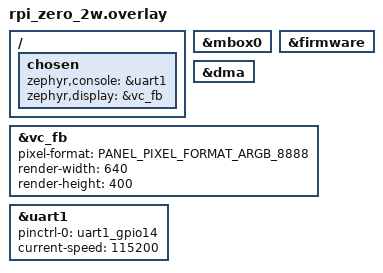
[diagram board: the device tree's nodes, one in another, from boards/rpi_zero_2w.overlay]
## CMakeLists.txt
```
# SPDX-License-Identifier: Apache-2.0
#
# PiZZa -- DOSBox-X on the shared SDL2 shim (apps/lib/sdl2shim).
#
# Links the DOSBox-X machine core (untouched checkout at
# ~/github/dosbox-x) against the shim, with the desktop chrome left out
# of the TU list and sdlmain.cpp replaced wholesale by
# src/sdlmain_embedded.cpp. TU selection and macro choices per
# notes/P2_SCOPE.md.
#
# DOSBox-X is GPL-2.0-or-later; this binary is GPL-2.0 by linking it.

cmake_minimum_required(VERSION 3.20.0)

find_package(Zephyr REQUIRED HINTS $ENV{ZEPHYR_BASE})
project(pizza-dosbox LANGUAGES C CXX ASM)

if(CONFIG_USB_DEVICE_STACK_NEXT)
  include(${ZEPHYR_BASE}/samples/subsys/usb/common/common.cmake)
endif()

# ── DOSBox-X tree (untouched) ───────────────────────────────────────
if(NOT DEFINED DBX)
  set(DBX "$ENV{HOME}/github/dosbox-x")
endif()
if(NOT EXISTS "${DBX}/src/dosbox.cpp")
  message(FATAL_ERROR
    "DOSBox-X sources not found at ${DBX}. Clone "
    "https://github.com/joncampbell123/dosbox-x or pass -DDBX=<path>.")
endif()
set(S ${DBX}/src)

# ── KEEP list (P2_SCOPE.md §5) ──────────────────────────────────────
# cpu: all cores except the x86-host-only dynamic_x86.
set(DBX_CPU
  ${S}/cpu/callback.cpp ${S}/cpu/cpu.cpp ${S}/cpu/flags.cpp
  ${S}/cpu/modrm.cpp ${S}/cpu/paging.cpp ${S}/cpu/mmx.cpp
  ${S}/cpu/core_full.cpp ${S}/cpu/core_simple.cpp
  ${S}/cpu/core_normal.cpp ${S}/cpu/core_normal_286.cpp
  ${S}/cpu/core_normal_8086.cpp ${S}/cpu/core_prefetch.cpp
  ${S}/cpu/core_prefetch_286.cpp ${S}/cpu/core_prefetch_8086.cpp
  ${S}/cpu/core_dynrec.cpp
)

set(DBX_FPU ${S}/fpu/fpu.cpp)

# dos: platform cdrom-ioctl variants and physfs dropped.
# cdrom_image.cpp rewritten in the build dir: the CHD prefetch thread
# (std::thread, no gthreads on Zephyr) is compiled out, taking the
# synchronous decode path instead. Checkout stays pristine (Doom
# i_video precedent).
set(DBX_CDIMG_GEN ${CMAKE_BINARY_DIR}/gen/cdrom_image_nothread.cpp)
add_custom_command(
  OUTPUT ${DBX_CDIMG_GEN}
  COMMAND ${CMAKE_COMMAND} -E make_directory ${CMAKE_BINARY_DIR}/gen
  COMMAND ${CMAKE_COMMAND} -E copy ${S}/dos/cdrom_image.cpp ${DBX_CDIMG_GEN}
  COMMAND sed -i.bak
          -e "s@#if !defined(HX_DOS) && !(defined(__MINGW32__) && !defined(__MINGW64_VERSION_MAJOR))@#if 0 /* no threads on Zephyr */@"
          -e "s@#if defined(HX_DOS) || defined(__MINGW32__) && !defined(__MINGW64_VERSION_MAJOR)@#if 1 /* sync CHD decode */@"
          ${DBX_CDIMG_GEN}
  DEPENDS ${S}/dos/cdrom_image.cpp
  COMMENT "Rewriting cdrom_image.cpp: CHD prefetch thread -> sync decode"
  VERBATIM
)

# dos_programs.cpp rewritten in the build dir: the physfs:// mount
# branches reference physfsDrive (vendored PhysFS not built); NULL the
# construction and casts, MOUNT reports failure on such paths.
set(DBX_DOSPROG_GEN ${CMAKE_BINARY_DIR}/gen/dos_programs_nophysfs.cpp)
add_custom_command(
  OUTPUT ${DBX_DOSPROG_GEN}
  COMMAND ${CMAKE_COMMAND} -E make_directory ${CMAKE_BINARY_DIR}/gen
  COMMAND ${CMAKE_COMMAND} -E copy ${S}/dos/dos_programs.cpp ${DBX_DOSPROG_GEN}
  COMMAND sed -i.bak
          -e "s@new physfscdromDrive@NULL; (void)@"
          -e "s@new physfsDrive@NULL; (void)@"
          -e "s@dynamic_cast<physfsDrive\\*>(Drives\\[drive-'A'\\])@NULL@"
          -e "s@dynamic_cast<physfscdromDrive\\*>(Drives\\[drive-'A'\\])@NULL@"
          ${DBX_DOSPROG_GEN}
  DEPENDS ${S}/dos/dos_programs.cpp
  COMMENT "Rewriting dos_programs.cpp: physfs mounts -> NULL"
  VERBATIM
)

# dos_files.cpp gets the same physfs treatment (savestate restore paths).
set(DBX_DOSFILES_GEN ${CMAKE_BINARY_DIR}/gen/dos_files_nophysfs.cpp)
add_custom_command(
  OUTPUT ${DBX_DOSFILES_GEN}
  COMMAND ${CMAKE_COMMAND} -E make_directory ${CMAKE_BINARY_DIR}/gen
  COMMAND ${CMAKE_COMMAND} -E copy ${S}/dos/dos_files.cpp ${DBX_DOSFILES_GEN}
  COMMAND sed -i.bak
          -e "s@if (strlen(overlaydir)) dynamic_cast<physfsDrive\\*>(Drives\\[lcv\\])->setOverlaydir(overlaydir);@;@"
          -e "s@dynamic_cast<physfsDrive\\*>(Drives\\[lcv\\])@NULL@g"
          -e "s@new physfscdromDrive@NULL; (void)@"
          -e "s@new physfsDrive@NULL; (void)@"
          ${DBX_DOSFILES_GEN}
  DEPENDS ${S}/dos/dos_files.cpp
  COMMENT "Rewriting dos_files.cpp: physfs savestate paths -> NULL"
  VERBATIM
)

set(DBX_DOS
  ${S}/dos/cdrom.cpp ${DBX_CDIMG_GEN}
  ${S}/dos/dos.cpp ${S}/dos/dos_classes.cpp ${S}/dos/dos_devices.cpp
  ${S}/dos/dos_execute.cpp ${DBX_DOSFILES_GEN} ${S}/dos/dos_ioctl.cpp
  ${S}/dos/dos_keyboard_layout.cpp ${S}/dos/dos_memory.cpp
  ${S}/dos/dos_misc.cpp ${S}/dos/dos_mscdex.cpp ${DBX_DOSPROG_GEN}
  ${S}/dos/dos_tables.cpp ${S}/dos/drive_cache.cpp ${S}/dos/drive_fat.cpp
  ${S}/dos/drive_iso.cpp ${S}/dos/drive_local.cpp
  ${S}/dos/drive_overlay.cpp ${S}/dos/drive_virtual.cpp
  ${S}/dos/drives.cpp ${S}/dos/eltorito.cpp
)

set(DBX_INTS
  ${S}/ints/bios.cpp ${S}/ints/bios_disk.cpp ${S}/ints/bios_keyboard.cpp
  ${S}/ints/bios_memdisk.cpp ${S}/ints/bios_vhd.cpp ${S}/ints/ems.cpp
  ${S}/ints/int10.cpp ${S}/ints/int10_char.cpp ${S}/ints/int10_memory.cpp
  ${S}/ints/int10_misc.cpp ${S}/ints/int10_modes.cpp
  ${S}/ints/int10_pal.cpp ${S}/ints/int10_put_pixel.cpp
  ${S}/ints/int10_vesa.cpp ${S}/ints/int10_video_state.cpp
  ${S}/ints/int10_vptable.cpp ${S}/ints/int_dosv.cpp ${S}/ints/mouse.cpp
  ${S}/ints/pc98_lio.cpp ${S}/ints/qcow2_disk.cpp ${S}/ints/xms.cpp
)

set(DBX_SHELL
  ${S}/shell/shell.cpp ${S}/shell/shell_batch.cpp
  ${S}/shell/shell_cmds.cpp ${S}/shell/shell_misc.cpp
)

# misc: ethernet dispatcher kept with the "nothing" backend only;
# pcap/slirp/ethnet and iconvpp dropped.
set(DBX_MISC
  ${S}/misc/clipboard.cpp ${S}/misc/cross.cpp ${S}/misc/ethernet.cpp
  ${S}/misc/ethernet_nothing.cpp ${S}/misc/messages.cpp
  ${S}/misc/mkdir_p.cpp ${S}/misc/programs.cpp
  ${S}/misc/regionalloctracking.cpp ${S}/misc/savestates.cpp
  ${S}/misc/setup.cpp ${S}/misc/shiftjis.cpp ${S}/misc/support.cpp
)

set(DBX_OUTPUT ${S}/output/output_surface.cpp ${S}/output/output_tools.cpp)

# gui: sdlmain.cpp REPLACED by sdlmain_embedded.cpp; sdl_gui/gui_tk and
# sdlmain_linux omitted.
# sdl_mapper.cpp rewritten in the build dir: the Typer autotype helper
# owns a std::thread (no gthreads on Zephyr); its start becomes a no-op.
set(DBX_MAPPER_GEN ${CMAKE_BINARY_DIR}/gen/sdl_mapper_nothread.cpp)
add_custom_command(
  OUTPUT ${DBX_MAPPER_GEN}
  COMMAND ${CMAKE_COMMAND} -E make_directory ${CMAKE_BINARY_DIR}/gen
  COMMAND ${CMAKE_COMMAND} -E copy ${S}/gui/sdl_mapper.cpp ${DBX_MAPPER_GEN}
  COMMAND sed -i.bak
          -e "s@m_instance = std::thread(&Typer::Callback, this);@/* autotype disabled (no threads) */@"
          -e "s@if (m_instance.joinable())@if (0)@"
          -e "s@m_instance.join();@{}@"
          -e "s@std::thread              m_instance;@/* no thread member */@"
          ${DBX_MAPPER_GEN}
  DEPENDS ${S}/gui/sdl_mapper.cpp
  COMMENT "Rewriting sdl_mapper.cpp: Typer std::thread -> no-op"
  VERBATIM
)

set(DBX_GUI
  ${S}/gui/bitop.cpp ${S}/gui/ptrop.cpp ${S}/gui/menu.cpp
  ${S}/gui/menu_callback.cpp ${S}/gui/midi.cpp ${S}/gui/render.cpp
  ${S}/gui/render_scalers.cpp ${DBX_MAPPER_GEN}
  ${S}/gui/zipcrc.c ${S}/gui/zipfile.cpp
)

# debug_gui carries LOG_MSG/logging even with C_DEBUG off.
set(DBX_DEBUG ${S}/debug/debug_gui.cpp)

# hardware: PC-98 display TUs kept dormant (symbols referenced from
# shared vga code); snd_pc98 + pc98_fm, voodoo/glide, network cards,
# serial-OPL boards, imfc (std::thread), innova (reSID) omitted.
set(DBX_HW
  ${S}/hardware/8255.cpp ${S}/hardware/adlib.cpp ${S}/hardware/cmos.cpp
  ${S}/hardware/cqm.c ${S}/hardware/dbopl.cpp ${S}/hardware/disney.cpp
  ${S}/hardware/dma.cpp ${S}/hardware/floppy.cpp
  ${S}/hardware/gameblaster.cpp ${S}/hardware/gus.cpp
  ${S}/hardware/hardware.cpp ${S}/hardware/ide.cpp
  ${S}/hardware/iohandler.cpp ${S}/hardware/joystick.cpp
  ${S}/hardware/keyboard.cpp ${S}/hardware/memory.cpp
  ${S}/hardware/mixer.cpp ${S}/hardware/mpu401.cpp
  ${S}/hardware/nukedopl.cpp ${S}/hardware/pc98.cpp
  ${S}/hardware/pc98_artic.cpp ${S}/hardware/pci_bus.cpp
  ${S}/hardware/pcspeaker.cpp ${S}/hardware/pic.cpp
  ${S}/hardware/ps1_sound.cpp ${S}/hardware/sblaster.cpp
  ${S}/hardware/tandy_sound.cpp ${S}/hardware/timer.cpp
  ${S}/hardware/vga.cpp ${S}/hardware/vga_ati.cpp
  ${S}/hardware/vga_attr.cpp ${S}/hardware/vga_crtc.cpp
  ${S}/hardware/vga_dac.cpp ${S}/hardware/vga_draw.cpp
  ${S}/hardware/vga_gfx.cpp ${S}/hardware/vga_memory.cpp
  ${S}/hardware/vga_misc.cpp ${S}/hardware/vga_other.cpp
  ${S}/hardware/vga_paradise.cpp ${S}/hardware/vga_pc98_cg.cpp
  ${S}/hardware/vga_pc98_crtc.cpp ${S}/hardware/vga_pc98_dac.cpp
  ${S}/hardware/vga_pc98_egc.cpp ${S}/hardware/vga_pc98_gdc.cpp
  ${S}/hardware/vga_pc98_gdc_draw.cpp ${S}/hardware/vga_s3.cpp
  ${S}/hardware/vga_seq.cpp ${S}/hardware/vga_tseng.cpp
  ${S}/hardware/vga_xga.cpp
  ${S}/hardware/esfmu/esfm.c ${S}/hardware/esfmu/esfm_registers.c
)

set(DBX_MAME
  ${S}/hardware/mame/fmopl.cpp ${S}/hardware/mame/saa1099.cpp
  ${S}/hardware/mame/sn76496.cpp ${S}/hardware/mame/ymdeltat.cpp
  ${S}/hardware/mame/ymf262.cpp
)

# serialport: no SDL_net consumers (softmodem/nullmodem/misc_util out);
# directserial needs real host termios, out (C_DIRECTSERIAL off).
# libserial compiles against the compat termios (its opens fail at
# runtime) and satisfies the serial-OPL boards below.
set(DBX_SERIAL
  ${S}/hardware/serialport/serialport.cpp
  ${S}/hardware/serialport/serialdummy.cpp
  ${S}/hardware/serialport/serialmouse.cpp
  ${S}/hardware/serialport/seriallog.cpp
  ${S}/hardware/serialport/serialfile.cpp
  ${S}/hardware/serialport/libserial.cpp
)

# adlib.cpp references the serial OPL boards + RetroWave unconditionally
# (runtime-gated on oplemu= choices we never use). RetroWave links real
# (compat termios suffices); the opl2/opl3duo boards own std::threads,
# so they are method stubs in lib_stubs.cpp instead.
set(DBX_OPLBOARDS
  ${S}/hardware/RetroWaveLib/RetroWave.c
  ${S}/hardware/RetroWaveLib/Protocol/Serial.c
  ${S}/hardware/RetroWaveLib/Board/OPL3.c
  ${S}/hardware/RetroWaveLib/Platform/POSIX_SerialPort.c
  ${S}/hardware/RetroWaveLib/RetroWave_DOSBoX.cpp
)

set(DBX_PARPORT
  ${S}/hardware/parport/parport.cpp
  ${S}/hardware/parport/filelpt.cpp
  ${S}/hardware/parport/printer_charmaps.cpp
)

# builtin DOS tools (baked binaries); glide2x + ne2000 bins omitted.
set(DBX_BUILTIN
  ${S}/builtin/25_com.cpp ${S}/builtin/28_com.cpp ${S}/builtin/4dos.cpp
  ${S}/builtin/50_com.cpp ${S}/builtin/append_exe.cpp
  ${S}/builtin/buffers_com.cpp ${S}/builtin/cdplay.cpp
  ${S}/builtin/chkdsk_exe.cpp ${S}/builtin/cwsdpmi_exe.cpp
  ${S}/builtin/cwsdpmi_exe_pc98.cpp ${S}/builtin/debug_exe.cpp
  ${S}/builtin/defrag_exe.cpp ${S}/builtin/device_com.cpp
  ${S}/builtin/diskcopy_exe.cpp ${S}/builtin/dos32a_exe.cpp
  ${S}/builtin/dos4gw_exe.cpp ${S}/builtin/dosidle_exe.cpp
  ${S}/builtin/dosmid.cpp ${S}/builtin/dsxmenu_exe_pc.cpp
  ${S}/builtin/dsxmenu_exe_pc98.cpp ${S}/builtin/edit_com.cpp
  ${S}/builtin/emsmagic.cpp ${S}/builtin/eval.cpp ${S}/builtin/fc_exe.cpp
  ${S}/builtin/fcbs_com.cpp ${S}/builtin/fdisk_exe.cpp
  ${S}/builtin/files_com.cpp ${S}/builtin/find_exe.cpp
  ${S}/builtin/format_exe.cpp ${S}/builtin/glide2x.cpp
  ${S}/builtin/ne2000bin.cpp ${S}/builtin/hexmem16_exe.cpp
  ${S}/builtin/hexmem32_exe.cpp ${S}/builtin/ipsmake.cpp
  ${S}/builtin/ipspatch.cpp ${S}/builtin/lastdriv_com.cpp
  ${S}/builtin/mem_com.cpp ${S}/builtin/move_exe.cpp
  ${S}/builtin/mpxplay.cpp ${S}/builtin/print_com.cpp
  ${S}/builtin/replace_exe.cpp ${S}/builtin/shutdown.cpp
  ${S}/builtin/sort_exe.cpp ${S}/builtin/sys_com.cpp
  ${S}/builtin/textutil.cpp ${S}/builtin/xcopy_exe.cpp
  ${S}/builtin/zip.cpp
)

# aviwriter: hardware.cpp references avi_writer_*/riff_wav_writer_*
# unconditionally (runtime-gated); self-contained, so link the real thing.
set(DBX_AVIWRITER
  ${S}/aviwriter/avi_writer.cpp ${S}/aviwriter/avi_rw_iobuf.cpp
  ${S}/aviwriter/guid.cpp ${S}/aviwriter/ksdataformat.cpp
  ${S}/aviwriter/riff.cpp ${S}/aviwriter/riff_wav_writer.cpp
)

# vendored zlib (vs/zlib): include/zip.h + savestates need it; the gz*
# file API is not used on the RAM-fd layer, left out.
set(DBX_ZLIB
  ${DBX}/vs/zlib/adler32.c ${DBX}/vs/zlib/compress.c
  ${DBX}/vs/zlib/crc32.c ${DBX}/vs/zlib/deflate.c
  ${DBX}/vs/zlib/infback.c ${DBX}/vs/zlib/inffast.c
  ${DBX}/vs/zlib/inflate.c ${DBX}/vs/zlib/inftrees.c
  ${DBX}/vs/zlib/trees.c ${DBX}/vs/zlib/uncompr.c
  ${DBX}/vs/zlib/zutil.c
)

# CD audio decoders: cdrom_image.cpp amalgamates SDL_sound.c + all
# decoder sources itself (that is also how upstream gives mp3.cpp its
# seek-table header) -- no standalone decoder TUs. Opus tracks resolve
# against the failing opusfile stubs in lib_stubs.cpp.
set(DBX_DECODERS)

# vendored libpng (vs/libpng): the bios.cpp boot splash decodes PNG
# unconditionally -- upstream treats libpng as part of the floor.
set(DBX_LIBPNG
  ${DBX}/vs/libpng/png.c ${DBX}/vs/libpng/pngerror.c
  ${DBX}/vs/libpng/pngget.c ${DBX}/vs/libpng/pngmem.c
  ${DBX}/vs/libpng/pngpread.c ${DBX}/vs/libpng/pngread.c
  ${DBX}/vs/libpng/pngrio.c ${DBX}/vs/libpng/pngrtran.c
  ${DBX}/vs/libpng/pngrutil.c ${DBX}/vs/libpng/pngset.c
  ${DBX}/vs/libpng/pngtrans.c ${DBX}/vs/libpng/pngwio.c
  ${DBX}/vs/libpng/pngwrite.c ${DBX}/vs/libpng/pngwtran.c
  ${DBX}/vs/libpng/pngwutil.c
)

set(DBX_SOURCES
  ${S}/dosbox.cpp
  ${DBX_CPU} ${DBX_FPU} ${DBX_DOS} ${DBX_INTS} ${DBX_SHELL} ${DBX_MISC}
  ${DBX_OUTPUT} ${DBX_GUI} ${DBX_DEBUG} ${DBX_HW} ${DBX_MAME}
  ${DBX_SERIAL} ${DBX_OPLBOARDS} ${DBX_PARPORT} ${DBX_BUILTIN}
  ${DBX_DECODERS} ${DBX_ZLIB} ${DBX_LIBPNG} ${DBX_AVIWRITER}
)

# ── shim + embedded platform layer ──────────────────────────────────
include(${CMAKE_CURRENT_SOURCE_DIR}/../lib/sdl2shim/sdl2shim.cmake)

# BT HID input (keyboard + mouse) via apps/lib/btinput -- rpi_zero_2w only
# (boards/rpi_zero_2w.conf sets CONFIG_BTINPUT; qemu has no radio).
if(CONFIG_BTINPUT)
  include(${CMAKE_CURRENT_SOURCE_DIR}/../lib/btinput/btinput.cmake)
  # The BT patchram (.hcd) is a gitignored vendor blob (PROVENANCE.md).
  # Fail LOUDLY if missing: an empty-patchram image wedges the controller
  # at runtime (Download_Minidriver with nothing to launch).
  if(NOT CONFIG_AIROC_CUSTOM_FIRMWARE_HCD_BLOB)
    message(FATAL_ERROR
      "DOSBox+BTINPUT: CONFIG_AIROC_CUSTOM_FIRMWARE_HCD_BLOB is unset")
  endif()
  set(_bt_blob "${CONFIG_AIROC_CUSTOM_FIRMWARE_HCD_BLOB}")
  if(NOT IS_ABSOLUTE "${_bt_blob}")
    set(_bt_blob "${CMAKE_CURRENT_SOURCE_DIR}/${_bt_blob}")
  endif()
  if(NOT EXISTS "${_bt_blob}")
    message(FATAL_ERROR
      "DOSBox+BTINPUT: BT patchram not found:\n  ${_bt_blob}\n"
      "It is gitignored (vendor blob) -- fetch it per "
      "apps/lib/btinput/firmware/PROVENANCE.md before building.")
  endif()
  target_sources(app PRIVATE ${BTINPUT_SOURCES} src/dosbox_btinput.c)
  target_include_directories(app PRIVATE ${BTINPUT_INCLUDE_DIRS})
endif()

set(DOSBOX_APP_SRC
  src/sdlmain_embedded.cpp
  src/posix_stubs.c
  src/abi_thunks.cpp
  src/lib_stubs.cpp
  src/sdl_compat.cpp
  src/dosbox_video.c
  src/dosbox_assets.c
  src/dosbox_dyncache.c
  src/dosbox_clock.c
  src/dosbox_pack.S
)

# baked FAT disk image (assets/<DBX_DISK> -> build dir for .incbin).
# DBX_DISK selects which image is baked; default is the DOOM HDD.
if(NOT DEFINED DBX_DISK)
  set(DBX_DISK doom.img)
endif()
set(DBX_DISK_BIN ${CMAKE_BINARY_DIR}/dosbox_disk.img)
add_custom_command(
  OUTPUT ${DBX_DISK_BIN}
  COMMAND ${CMAKE_COMMAND} -E copy ${CMAKE_CURRENT_SOURCE_DIR}/assets/${DBX_DISK} ${DBX_DISK_BIN}
  DEPENDS ${CMAKE_CURRENT_SOURCE_DIR}/assets/${DBX_DISK}
  COMMENT "Baking FAT disk image ${DBX_DISK} into rodata"
)
add_custom_target(dbx_disk_bake DEPENDS ${DBX_DISK_BIN})
add_dependencies(app dbx_disk_bake)
set_source_files_properties(src/dosbox_pack.S PROPERTIES
  OBJECT_DEPENDS ${DBX_DISK_BIN}
  COMPILE_OPTIONS "-I${CMAKE_BINARY_DIR};-Wa,-I${CMAKE_BINARY_DIR}"
)

# dynrec code-cache dual-map patch: a build-dir copy of
# cpu/dynamic_alloc_common.h with the Zephyr branch injected. gen/ is
# prepended to the include path (below), so core_dynrec.cpp's
# `#include "cpu/dynamic_alloc_common.h"` resolves to the patched copy;
# checkout stays pristine.
set(DBX_DYNALLOC_GEN ${CMAKE_BINARY_DIR}/gen/cpu/dynamic_alloc_common.h)
add_custom_command(
  OUTPUT ${DBX_DYNALLOC_GEN}
  COMMAND ${CMAKE_COMMAND} -E make_directory ${CMAKE_BINARY_DIR}/gen/cpu
  COMMAND ${PYTHON_EXECUTABLE} ${CMAKE_CURRENT_SOURCE_DIR}/patch_dyncache.py
          ${S}/cpu/dynamic_alloc_common.h ${DBX_DYNALLOC_GEN}
  DEPENDS ${S}/cpu/dynamic_alloc_common.h ${CMAKE_CURRENT_SOURCE_DIR}/patch_dyncache.py
  COMMENT "Patching dynamic_alloc_common.h with the Zephyr dual-map branch"
)
add_custom_target(dbx_dynalloc_patch DEPENDS ${DBX_DYNALLOC_GEN})
add_dependencies(app dbx_dynalloc_patch)

if(CONFIG_DOSBOX_PRESENT_SEMIHOST)
  list(APPEND DOSBOX_APP_SRC src/dosbox_present_semihost.c)
elseif(CONFIG_DOSBOX_PRESENT_DISPLAY)
  list(APPEND DOSBOX_APP_SRC src/dosbox_present_display.c)
else()
  list(APPEND DOSBOX_APP_SRC src/dosbox_present_none.c)
endif()

if(CONFIG_DOSBOX_SCRIPTED_INPUT)
  list(APPEND DOSBOX_APP_SRC src/dosbox_scripted.c)
endif()

if(CONFIG_SDL2SHIM_AUDIO_HDMI)
  list(APPEND DOSBOX_APP_SRC ${SDL2SHIM_AUDIO_HDMI_SOURCES})
else()
  list(APPEND DOSBOX_APP_SRC ${SDL2SHIM_AUDIO_NONE})
endif()
if(CONFIG_USB_DEVICE_STACK_NEXT)
  list(APPEND DOSBOX_APP_SRC ${SDL2SHIM_USB})
endif()

target_sources(app PRIVATE
  ${DBX_SOURCES}
  ${DOSBOX_APP_SRC}
  ${SDL2SHIM_CORE_SOURCES}
)

# include order: our compat dir first (config.h + header stubs), then
# the shim SDL2 headers (both <SDL2/SDL.h> and bare "SDL.h" forms),
# then the DOSBox-X tree.
target_include_directories(app PRIVATE
  ${CMAKE_CURRENT_SOURCE_DIR}/src/compat
  ${SDL2SHIM_INCLUDE_DIRS}
  ${CMAKE_CURRENT_SOURCE_DIR}/../lib/sdl2shim/include/SDL2
  ${DBX}/include
  ${DBX}/vs
  ${DBX}/vs/zlib
  ${DBX}/vs/libpng
  ${DBX}
  ${CMAKE_BINARY_DIR}/gen   # patched cpu/dynamic_alloc_common.h wins over src/
  ${S}
  ${S}/libs/decoders
  ${S}/aviwriter
  ${S}/dos
  ${S}/hardware
)

# DOSBox-X TUs assume a glibc-ish environment; keep upstream's warning
# posture and give picolibc the BSD/POSIX visibility it expects.
set(DBX_FLAGS
  "-DPNG_ARM_NEON_OPT=0;-include;${CMAKE_CURRENT_SOURCE_DIR}/src/compat/config.h;-Wno-unused-variable;-Wno-unused-but-set-variable;-Wno-unused-function;-Wno-missing-braces;-Wno-implicit-fallthrough;-Wno-format;-Wno-maybe-uninitialized;-Wno-sign-compare;-Wno-parentheses;-Wno-misleading-indentation;-Wno-write-strings;-Wno-class-memaccess;-Wno-deprecated-declarations;-D_DEFAULT_SOURCE;$<$<COMPILE_LANGUAGE:C>:-Wno-int-conversion>;$<$<COMPILE_LANGUAGE:C>:-Wno-implicit-function-declaration>"
)
set_source_files_properties(${DBX_SOURCES} PROPERTIES COMPILE_OPTIONS "${DBX_FLAGS}")
```

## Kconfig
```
# SPDX-License-Identifier: Apache-2.0
#
# PiZZa DOSBox-X port -- app options.

# SAMPLE_USBD_* options for sample_usbd_init.c on boards with the USB
# device stack (rpi_zero_2w).
source "samples/subsys/usb/common/Kconfig.sample_usbd"

rsource "../lib/sdl2shim/Kconfig"
rsource "../lib/btinput/Kconfig"

menu "PiZZa DOSBox-X port"

choice DOSBOX_PRESENT_BACKEND
	prompt "Frame present backend"
	default DOSBOX_PRESENT_DISPLAY if DISPLAY
	default DOSBOX_PRESENT_SEMIHOST if QEMU_TARGET
	default DOSBOX_PRESENT_NONE

config DOSBOX_PRESENT_DISPLAY
	bool "Zephyr display API (bcm2835_fb + HVS scaling on hardware)"
	depends on DISPLAY

config DOSBOX_PRESENT_SEMIHOST
	bool "Semihosting PPM frame capture (qemu sim gates)"

config DOSBOX_PRESENT_NONE
	bool "Discard frames"

endchoice

config DOSBOX_CAPTURE_EVERY
	int "Capture every Nth frame (semihost backend)"
	depends on DOSBOX_PRESENT_SEMIHOST
	default 200

config DOSBOX_SCRIPTED_INPUT
	bool "Scripted keyboard input at the DOS prompt (sim verification)"
	default n

endmenu

source "Kconfig.zephyr"
```

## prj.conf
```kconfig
# SPDX-License-Identifier: Apache-2.0
#
# Common config for the PiZZa DOSBox-X port. Per-board overrides live in
# boards/<board>.conf.

CONFIG_PRINTK=y
CONFIG_BOOT_BANNER=y
CONFIG_LOG_PRINTK=n

# picolibc errno needs TLS -- same stanza as wipeout/SDLPoP/Doom.
CONFIG_TOOLCHAIN_CROSS_COMPILE_SUPPORTS_THREAD_LOCAL_STORAGE=y
CONFIG_THREAD_LOCAL_STORAGE=y

# C++17 + real libstdc++ (aarch64 recipe: also pass
# -DTOOLCHAIN_HAS_GLIBCXX=ON on the west line). DOSBox-X throws through
# E_Exit/reboot paths, so exceptions are on.
CONFIG_CPP=y
CONFIG_STD_CPP17=y
CONFIG_GLIBCXX_LIBCPP=y
CONFIG_CPP_EXCEPTIONS=y
# the config system (Section_prop) dynamic_casts pervasively
CONFIG_CPP_RTTI=y

# Guest RAM (memsize) + VGA memory + surfaces + the 6.7 MiB DOOM disk
# RAM-staging + STL. The dynrec code cache is a separate 8.4 MiB static
# arena (dosbox_dyncache.c), not from this pool. 128 MiB is comfortable
# on the 256 MiB (qemu overlay) / 512 MiB (rpi_zero_2w) targets.
CONFIG_COMMON_LIBC_MALLOC_ARENA_SIZE=134217728

# DOS kernel + shell call chains run deep; normal core recursion too.
CONFIG_MAIN_STACK_SIZE=262144

CONFIG_FPU=y
CONFIG_STACK_SENTINEL=y
CONFIG_ASSERT=y

# dynrec dual-map: two 8.4 MiB RW/RX aliases at 64 KiB granule on top of
# the image + SoC device maps need extra translation tables (P0 recipe).
CONFIG_MAX_XLAT_TABLES=32
```

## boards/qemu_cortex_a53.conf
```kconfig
# SPDX-License-Identifier: Apache-2.0
# qemu sim gates: PPM frame capture over semihosting + scripted typing.
CONFIG_SEMIHOST=y
CONFIG_DOSBOX_SCRIPTED_INPUT=y
# DOOM under TCG renders slowly; capture often to catch game frames.
CONFIG_DOSBOX_CAPTURE_EVERY=3
# 256 MiB qemu RAM (paired with the sram0 overlay); the board default
# 128 MiB is too tight for the full DOSBox-X + DOOM working set.
CONFIG_QEMU_EXTRA_FLAGS="-m 256M"
```

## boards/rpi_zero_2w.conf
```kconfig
# SPDX-License-Identifier: Apache-2.0
#
# Raspberry Pi Zero 2 W (BCM2710, Cortex-A53, AArch64) -- DOSBox-X.
# First HW light: the DOOM/DOS4GW dynrec perf gate on the panel. The
# baked DOOM HDD auto-mounts and `doom -timedemo demo3` runs on boot
# (dosbox_scripted.c); video goes to HDMI, logs + the timing result to
# the mini-UART console. Single core (DOSBox CPU emulation is
# single-threaded), no USB, no audio yet (that is P2e).

CONFIG_BOOT_DELAY=200

# VC mailbox + firmware (framebuffer alloc chain).
CONFIG_RASPBERRYPI_FIRMWARE=y

# HDMI display via VC firmware FB, ARGB_8888, fixed 640x400 virtual mode;
# dosbox_present_display.c scales each DOSBox mode into it and the HVS
# scales 640x400 to the monitor. Requires hdmi_drive=2 in config.txt.
CONFIG_DISPLAY=y
CONFIG_BCM2835_FB=y
CONFIG_DMA=y
CONFIG_DMA_BCM2835=y

# HDMI audio via VC4 MAI (same backend the Doom port HW-verified): the
# DOSBox mixer's 44.1 kHz output is resampled to 48 kHz, IEC958-packed
# and DMA-fed into the MAI FIFO. FB blit + MAI feed use separate DMA
# channels; the cyclic MAI ring needs 8 control blocks. Requires
# hdmi_drive=2 and a display that accepts audio (TV, not DVI).
CONFIG_SDL2SHIM_AUDIO_HDMI=y
CONFIG_DMA_BCM2835_MAX_CBS_PER_CHANNEL=8

# Auto-run the timedemo at the DOS prompt (the perf gate).
CONFIG_DOSBOX_SCRIPTED_INPUT=y

# Zephyr's usable region on this board is 256 MiB (from 0x200000; the VC
# firmware owns the rest). 160 MiB arena holds the guest RAM + VGA mem +
# the 6.7 MiB DOOM disk RAM-staging + STL, leaving headroom for the code,
# builtins, DOOM image rodata and the separate 8.4 MiB dynrec cache.
CONFIG_COMMON_LIBC_MALLOC_ARENA_SIZE=167772160

# Logging on the mini-UART console.
CONFIG_LOG=y
CONFIG_LOG_BUFFER_SIZE=16384
CONFIG_LOG_BACKEND_UART=y
CONFIG_LOG_MODE_DEFERRED=y

# ── Bluetooth HID input (M4.5 demo: 8BitDo pad + BT mouse into DOOM) ──
# The stack, host profile and connection policy all live in
# apps/lib/btinput; config below mirrors the HW-proven bring-up harness
# settings minus the harness-only debug knobs.
CONFIG_BTINPUT=y
CONFIG_BTINPUT_HOGP=y
CONFIG_BTINPUT_SEAM_SDL=y
CONFIG_BTINPUT_MANAGER=y

CONFIG_BT=y
CONFIG_BT_CLASSIC=y
CONFIG_BT_DEVICE_NAME="PiZZa"
CONFIG_BT_MAX_PAIRED=8
CONFIG_BT_MAX_CONN=3
# The 8BitDo's fw is legacy-only SMP; Just Works is the accepted trust model.
CONFIG_BT_SMP_SC_PAIR_ONLY=n
# The 4.2 controller has 1M PHY only; skip the doomed LE Set PHY attempt.
CONFIG_BT_AUTO_PHY_UPDATE=n

# Infineon AIROC patchram: this unit is the Synaptics 43436S module
# (BT ROM = 43430A1). Blob is gitignored; PROVENANCE.md has the fetch.
CONFIG_BT_AIROC=y
CONFIG_BT_AIROC_CUSTOM=y
CONFIG_AIROC_CUSTOM_FIRMWARE_HCD_BLOB="../lib/btinput/firmware/SYN43430A1.hcd"

# Bond persistence: settings FILE backend on the SD FAT (the manager
# mounts /SD: itself; MKFS off -- a failed mount degrades to RAM bonds).
CONFIG_BT_SETTINGS=y
CONFIG_SETTINGS=y
CONFIG_SETTINGS_FILE=y
CONFIG_SETTINGS_FILE_PATH="/SD:/bt/settings"
CONFIG_DISK_ACCESS=y
CONFIG_DISK_DRIVERS=y
CONFIG_SDMMC_SUBSYS=y
CONFIG_FILE_SYSTEM=y
CONFIG_FAT_FILESYSTEM_ELM=y
CONFIG_FS_FATFS_LFN=y
CONFIG_FILE_SYSTEM_MKFS=n
CONFIG_FS_FATFS_MOUNT_MKFS=n

# aarch64: BT stack defaults are Cortex-M sized; P-256 on the long WQ
# needs 8K frames (instruction-abort class otherwise).
CONFIG_BT_LONG_WQ_STACK_SIZE=8192
CONFIG_BT_RX_STACK_SIZE=8192
CONFIG_BT_HCI_TX_STACK_SIZE_WITH_PROMPT=y
CONFIG_BT_HCI_TX_STACK_SIZE=4096
CONFIG_SYSTEM_WORKQUEUE_STACK_SIZE=8192
CONFIG_THREAD_NAME=y

# ELM FatFs is NOT thread-safe by default; the bond store is written from
# the btinput manager thread + system workqueue. Any second FatFs user in
# this app would race it (that combination silently lost every bond save
# in the minivmac image, HW 2026-07-08) -- keep the per-volume mutex on.
# REENTRANT requires the LFN buffer off BSS (stack mode).
CONFIG_FS_FATFS_REENTRANT=y
CONFIG_FS_FATFS_LFN_MODE_STACK=y

# A re-pairing peer whose new identity info (IRK) resolves an EXISTING bond
# entry is otherwise REFUSED by smp.c ("the old bond must be unpaired
# first") -- observed with the MX Master after bond litter accumulated
# under its rotating addresses (HW 2026-07-08): every reconnect became a
# pairing attempt that conflicted with a stale bond, mouse unreachable.
# With this, the stack unpairs the conflicting stale bond (trust-checked)
# and the pairing completes -- self-healing, no card surgery.
CONFIG_BT_ID_UNPAIR_MATCHING_BONDS=y
# ...and the trust check's final branch refuses JW-over-JW overwrites
# without this (smp.c update_keys_check: "old bond has more trust").
# JW has no MITM protection anyway -- the WO-accepted trust model.
CONFIG_BT_SMP_ALLOW_UNAUTH_OVERWRITE=y
```

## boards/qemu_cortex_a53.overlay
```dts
/* SPDX-License-Identifier: Apache-2.0
 *
 * DOSBox-X on qemu needs more than the board's default 128 MiB (guest
 * RAM + VGA memory + dynrec cache + the baked DOOM image + STL). The
 * real target (rpi_zero_2w) has 512 MiB, so this is a sim-only lift.
 * Paired with CONFIG_QEMU_EXTRA_FLAGS="-m 256M" in the board .conf.
 */

&sram0 {
	reg = <0x0 0x40000000 0x0 DT_SIZE_M(256)>;
};
```

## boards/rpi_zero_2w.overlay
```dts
/*
 * SPDX-License-Identifier: Apache-2.0
 *
 * PiZZa DOSBox-X overlay for rpi_zero_2w.
 *
 *   - &mbox0 + &firmware: VC mailbox + property tags (FB alloc).
 *   - &vc_fb: HDMI framebuffer pinned at a fixed 640x400 virtual mode;
 *     dosbox_present_display.c nearest-neighbor scales each DOSBox video
 *     mode into it and the VideoCore HVS scales 640x400 to the cable.
 *     DOOM presents at 640x400, so its frames land 1:1. 640 * 4 = 2560
 *     bytes/row = 64-byte aligned, so the FB driver's contiguous-DMA
 *     fast path engages.
 *   - &dma: BCM2835 DMA (backbuffer -> fb blit).
 *   - mini-UART (uart1) console + LOG target, PiZZa convention.
 */

#include <zephyr/dt-bindings/display/panel.h>

&mbox0 {
	status = "okay";
};

&firmware {
	status = "okay";
};

&dma {
	status = "okay";
};

&vc_fb {
	pixel-format = <PANEL_PIXEL_FORMAT_ARGB_8888>;
	render-width = <640>;
	render-height = <400>;
	status = "okay";
};

/ {
	chosen {
		zephyr,console = &uart1;
		zephyr,display = &vc_fb;
	};
};

&uart1 {
	pinctrl-names = "default";
	pinctrl-0 = <&uart1_gpio14>;
	status = "okay";
	current-speed = <115200>;
};
```

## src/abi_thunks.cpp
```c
/* iostream seek ABI thunks.
 *
 * Zephyr's zephyr_stdint.h remaps __INT64_TYPE__ to long long, so
 * libstdc++ headers typedef std::streamoff as long long at compile
 * time — but the SDK's prebuilt libstdc++.a was compiled with
 * streamoff = long. Same LP64 register layout, different mangled
 * names. These thunks alias the long-long-mangled calls onto the
 * library's long-mangled definitions.
 */

extern "C" {

/* std::istream::seekg(streamoff, seekdir) */
void *_ZNSi5seekgElSt12_Ios_Seekdir(void *self, long off, int dir);
void *_ZNSi5seekgExSt12_Ios_Seekdir(void *self, long long off, int dir)
{
	return _ZNSi5seekgElSt12_Ios_Seekdir(self, (long)off, dir);
}

/* std::basic_streambuf<char>::seekoff(streamoff, seekdir, openmode);
 * returns fpos<mbstate_t> = { streamoff, mbstate } in x0/x1 both ways.
 */
typedef struct { long long off; long long state; } fpos16;
fpos16 _ZNSt15basic_streambufIcSt11char_traitsIcEE7seekoffElSt12_Ios_SeekdirSt13_Ios_Openmode(
	void *self, long off, int dir, int mode);
fpos16 _ZNSt15basic_streambufIcSt11char_traitsIcEE7seekoffExSt12_Ios_SeekdirSt13_Ios_Openmode(
	void *self, long long off, int dir, int mode)
{
	return _ZNSt15basic_streambufIcSt11char_traitsIcEE7seekoffElSt12_Ios_SeekdirSt13_Ios_Openmode(
		self, (long)off, dir, mode);
}

} /* extern "C" */
```

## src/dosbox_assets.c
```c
/*
 * SPDX-License-Identifier: Apache-2.0
 *
 * PiZZa DOSBox-X -- baked-asset fd layer (Doom doom_assets.c pattern).
 *
 * The FAT floppy image is linked into .rodata (dosbox_pack.S) and
 * copied into a RAM buffer on first open, so IMGMOUNT's read-write
 * fopen works and DOS can write files onto A:. picolibc tinystdio
 * funnels fopen/fread/fseek/fwrite through open/read/lseek/write/
 * close/fstat, all of which resolve here. Everything that is not the
 * floppy image is ENOENT (config files, mapper files: absent by
 * design, their callers fall back to defaults).
 */

#include <zephyr/kernel.h>
#include <zephyr/sys/printk.h>
#include <errno.h>
#include <fcntl.h>
#include <stdint.h>
#include <stdlib.h>
#include <string.h>
#include <strings.h>
#include <sys/stat.h>
#include <sys/types.h>
#include <unistd.h>

extern const uint8_t dbx_disk_start[];
extern const uint8_t dbx_disk_end[];

#define DBX_FD_BASE 3
#define DBX_FD_MAX  8

static struct {
	bool used;
	size_t pos;
} fds[DBX_FD_MAX];

static uint8_t *disk_ram;
static size_t disk_size;

static bool is_image(const char *path)
{
	if (path == NULL) {
		return false;
	}

	size_t n = strlen(path);

	return n >= 4 && strcasecmp(path + n - 4, ".img") == 0;
}

static bool disk_ready(void)
{
	if (disk_ram != NULL) {
		return true;
	}
	disk_size = (size_t)(dbx_disk_end - dbx_disk_start);
	if (disk_size == 0) {
		return false;
	}
	disk_ram = malloc(disk_size);
	if (disk_ram == NULL) {
		return false;
	}
	memcpy(disk_ram, dbx_disk_start, disk_size);
	printk("[dbx] disk image staged to RAM (%u KiB)\n",
	       (unsigned)(disk_size / 1024));
	return true;
}

int open(const char *path, int flags, ...)
{
	(void)flags;
	if (!is_image(path) || !disk_ready()) {
		errno = ENOENT;
		return -1;
	}

	for (int i = 0; i < DBX_FD_MAX; i++) {
		if (!fds[i].used) {
			fds[i].used = true;
			fds[i].pos = 0;
			return DBX_FD_BASE + i;
		}
	}
	errno = EMFILE;
	return -1;
}

static int fd_slot(int fd)
{
	int i = fd - DBX_FD_BASE;

	if (i < 0 || i >= DBX_FD_MAX || !fds[i].used) {
		return -1;
	}
	return i;
}

int close(int fd)
{
	int i = fd_slot(fd);

	if (i < 0) {
		errno = EBADF;
		return -1;
	}
	fds[i].used = false;
	return 0;
}

ssize_t read(int fd, void *buf, size_t count)
{
	int i = fd_slot(fd);

	if (i < 0) {
		errno = EBADF;
		return -1;
	}

	size_t avail = disk_size - fds[i].pos;
	size_t n = MIN(count, avail);

	memcpy(buf, disk_ram + fds[i].pos, n);
	fds[i].pos += n;
	return (ssize_t)n;
}

ssize_t write(int fd, const void *buf, size_t count)
{
	int i = fd_slot(fd);

	if (i < 0) {
		errno = EBADF;
		return -1;
	}

	size_t space = disk_size - fds[i].pos;
	size_t n = MIN(count, space);

	memcpy(disk_ram + fds[i].pos, buf, n);
	fds[i].pos += n;
	if (n < count) {
		errno = ENOSPC;
	}
	return (ssize_t)n;
}

off_t lseek(int fd, off_t offset, int whence)
{
	int i = fd_slot(fd);

	if (i < 0) {
		errno = EBADF;
		return (off_t)-1;
	}

	off_t base;

	switch (whence) {
	case SEEK_SET: base = 0; break;
	case SEEK_CUR: base = (off_t)fds[i].pos; break;
	case SEEK_END: base = (off_t)disk_size; break;
	default:
		errno = EINVAL;
		return (off_t)-1;
	}

	off_t target = base + offset;

	if (target < 0 || target > (off_t)disk_size) {
		errno = EINVAL;
		return (off_t)-1;
	}
	fds[i].pos = (size_t)target;
	return target;
}

int fstat(int fd, struct stat *st)
{
	int i = fd_slot(fd);

	if (i < 0) {
		errno = EBADF;
		return -1;
	}
	memset(st, 0, sizeof(*st));
	st->st_size = (off_t)disk_size;
	st->st_mode = S_IFREG | 0644;
	return 0;
}

int stat(const char *path, struct stat *st)
{
	if (!is_image(path) || !disk_ready()) {
		errno = ENOENT;
		return -1;
	}
	memset(st, 0, sizeof(*st));
	st->st_size = (off_t)disk_size;
	st->st_mode = S_IFREG | 0644;
	return 0;
}

int access(const char *path, int mode)
{
	(void)mode;
	if (!is_image(path) || !disk_ready()) {
		errno = ENOENT;
		return -1;
	}
	return 0;
}
```

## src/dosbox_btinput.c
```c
/*
 * SPDX-License-Identifier: Apache-2.0
 *
 * PiZZa DOSBox-X -- Bluetooth HID input (CONFIG_BTINPUT).
 *
 * The whole BT stack lives in apps/lib/btinput: the manager owns bring-up +
 * connection policy, the SDL seam feeds events into the sdl2shim queue that
 * GFX_Events already drains. This TU is only consumer policy: the 8BitDo
 * Micro's stock K-mode keymap is letters (C..S), so remap its buttons onto
 * the keys DOOM (and DOS games generally) expect. Any other BT keyboard
 * passes through unmapped -- HID usages are SDL scancodes 1:1.
 */

#include <zephyr/kernel.h>

#include <SDL2/SDL.h>

#include "btinput.h"

/* 8BitDo Micro, K mode, stock map (HANDOVER §4). Usages 0x0e/0x0f/0x10/0x15
 * surfaced in a free-mash and belong to L2/R2/Plus/Minus/Star in some order
 * (the one-at-a-time mini-pass is still owed); their mappings below are
 * provisional. Home (0x16) also fires during the pad's power-off long-press;
 * Escape is harmless there.
 */
static const struct btinput_seam_key pad_map[] = {
	{ 0x06, SDL_SCANCODE_UP },     /* d-pad Up    (C)          */
	{ 0x07, SDL_SCANCODE_DOWN },   /* d-pad Down  (D)          */
	{ 0x08, SDL_SCANCODE_LEFT },   /* d-pad Left  (E)          */
	{ 0x09, SDL_SCANCODE_RIGHT },  /* d-pad Right (F)          */
	{ 0x0a, SDL_SCANCODE_LCTRL },  /* A (G) -> fire            */
	{ 0x0d, SDL_SCANCODE_SPACE },  /* B (J) -> use/open        */
	{ 0x0b, SDL_SCANCODE_RETURN }, /* X (H) -> menu select     */
	{ 0x0c, SDL_SCANCODE_ESCAPE }, /* Y (I) -> menu            */
	{ 0x12, SDL_SCANCODE_COMMA },  /* L (O) -> strafe left     */
	{ 0x11, SDL_SCANCODE_PERIOD }, /* R (N) -> strafe right    */
	{ 0x16, SDL_SCANCODE_ESCAPE }, /* Home                     */
	{ 0x0e, SDL_SCANCODE_Y },      /* provisional: 'y' confirm */
	{ 0x0f, SDL_SCANCODE_N },      /* provisional: 'n' cancel  */
	{ 0x10, SDL_SCANCODE_RETURN }, /* provisional              */
	{ 0x15, SDL_SCANCODE_TAB },    /* provisional: automap     */
};

void dbx_btinput_start(void)
{
	btinput_seam_sdl_set_keymap(pad_map, ARRAY_SIZE(pad_map));
	btinput_seam_sdl_set_bounds(640, 400);
	btinput_seam_sdl_attach();
	btinput_manager_start();
}
```

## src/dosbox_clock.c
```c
/*
 * SPDX-License-Identifier: Apache-2.0
 *
 * PiZZa DOSBox-X -- ARM clock bump (rpi_zero_2w).
 *
 * The VideoCore firmware idles the Cortex-A53 at arm_freq_min (~600 MHz)
 * unless something explicitly requests the turbo clock; Zephyr runs no
 * cpufreq governor. A DOS emulator is CPU-bound (the dynrec emulating
 * 386 protected mode), so at the idle clock DOOM runs ~60% of a 1 GHz
 * pace -- slow-motion. A boot-time SET_CLOCK_RATE with
 * skip_setting_turbo=0 pins the A53 at its rated 1.0 GHz (measured ~1.6x
 * on the Jet port). Opt-in per-app, per [[jet-arm-1ghz-bump]].
 */

#include <zephyr/kernel.h>
#include <zephyr/device.h>
#include <zephyr/sys/printk.h>

#if defined(CONFIG_RASPBERRYPI_FIRMWARE)

#include <rpi_fw.h>

#define VC_CLOCK_ID_ARM 3U
#define ARM_TARGET_HZ   1000000000U

void dbx_bump_arm_clock(void)
{
	const struct device *fw = DEVICE_DT_GET_ONE(raspberrypi_bcm283x_firmware);

	if (!device_is_ready(fw)) {
		printk("[dbx] VC firmware not ready -- ARM stays at idle clock\n");
		return;
	}

	uint32_t cur[2] = {VC_CLOCK_ID_ARM, 0U};

	rpi_fw_transfer(fw, RPI_FW_TAG_GET_CLOCK_RATE, cur, sizeof(cur));

	uint32_t req[3] = {VC_CLOCK_ID_ARM, ARM_TARGET_HZ, 0U /* skip_setting_turbo */};
	int err = rpi_fw_transfer(fw, RPI_FW_TAG_SET_CLOCK_RATE, req, sizeof(req));

	uint32_t post[2] = {VC_CLOCK_ID_ARM, 0U};

	rpi_fw_transfer(fw, RPI_FW_TAG_GET_CLOCK_RATE, post, sizeof(post));

	printk("[dbx] ARM clock: %u -> %u Hz (SET err=%d)\n",
	       (unsigned)cur[1], (unsigned)post[1], err);
}

#else /* no VC firmware (e.g. qemu) */

void dbx_bump_arm_clock(void) {}

#endif
```

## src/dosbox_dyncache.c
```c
/*
 * SPDX-License-Identifier: Apache-2.0
 *
 * PiZZa DOSBox-X -- dynrec code-cache backing (P0 dual-map W^X).
 *
 * Zephyr's arm64 MMU force-PXNs any writable normal mapping, so
 * dosbox-x's single-RWX and malloc code-cache paths cannot execute.
 * P0 (pizza-dynrec-probe, HW-verified on rpi_zero_2w) proved the fix:
 * a static arena mapped twice -- one RW alias to emit blocks, one RX
 * alias to run them, constant delta between them -- with stock
 * __builtin___clear_cache flushing on the RW VA. dosbox-x's dual-map
 * machinery (cache_rwtox / DYNCOREM_DUAL_RW_X) consumes exactly this.
 *
 * The patched dynamic_alloc_common.h (build-dir gen copy) calls
 * pizza_dyncache_map() as its first allocation attempt.
 */

#include <zephyr/kernel.h>
#include <zephyr/kernel/mm.h>
#include <zephyr/sys/printk.h>

/* kernel-internal arch API (kernel/include/kernel_arch_interface.h) */
extern void arch_mem_map(void *virt, uintptr_t phys, size_t size, uint32_t flags);

/* CACHE_TOTAL(8M) + CACHE_MAXSIZE(8K) + PAGESIZE_TEMP, rounded up to a
 * whole number of 64 KiB MMU granules (129 * 64 KiB = 8.4 MiB).
 */
#define ARENA_SIZE (129u * 64u * 1024u)
#define VA_RW      0x80000000UL
#define VA_RX      0x81000000UL

static uint8_t dyn_arena[ARENA_SIZE] __aligned(64 * 1024);
static bool mapped;

/* returns the RW alias base; *exec_ptr = the RX alias base */
uint8_t *pizza_dyncache_map(size_t size, uint8_t **exec_ptr)
{
	if (size > ARENA_SIZE) {
		printk("[dbx] dyncache: request %zu > arena %u\n", size, ARENA_SIZE);
		return NULL;
	}
	if (!mapped) {
		uintptr_t pa = (uintptr_t)dyn_arena; /* flat map, VM_OFFSET=0 */

		arch_mem_map((void *)VA_RW, pa, ARENA_SIZE,
			     K_MEM_CACHE_WB | K_MEM_PERM_RW);
		arch_mem_map((void *)VA_RX, pa, ARENA_SIZE,
			     K_MEM_CACHE_WB | K_MEM_PERM_EXEC);
		mapped = true;
		printk("[dbx] dyncache: %u KiB arena, RW@0x%lx RX@0x%lx (phys 0x%lx)\n",
		       ARENA_SIZE / 1024, VA_RW, VA_RX, pa);
	}
	*exec_ptr = (uint8_t *)VA_RX;
	return (uint8_t *)VA_RW;
}
```

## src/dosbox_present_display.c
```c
/*
 * SPDX-License-Identifier: Apache-2.0
 *
 * PiZZa DOSBox-X -- display present backend (CONFIG_DOSBOX_PRESENT_DISPLAY).
 *
 * DOSBox-X changes video mode at runtime (VGA text 720x400, the DOSBox
 * logo 640x480, DOOM's 640x400, ...), but the Zephyr display API has a
 * fixed resolution set at probe. So the VC framebuffer is pinned at a
 * fixed 640x400 virtual mode (render-width/height in the overlay) and
 * each incoming frame is nearest-neighbor scaled into it; the VideoCore
 * HVS then scales 640x400 to the monitor's native mode -- the same
 * proven trick as the Jet / wipeout / SDLPoP / Doom ports.
 *
 * 640x400 is chosen so DOOM (which DOSBox presents at 640x400) lands
 * 1:1, no resampling on the showcase path. DOSBox pixels are already
 * 0x00RRGGBB; the scanout wants 0xFFRRGGBB, so alpha is forced opaque.
 */

#include <zephyr/kernel.h>
#include <zephyr/device.h>
#include <zephyr/drivers/display.h>
#include <zephyr/logging/log.h>

#include "sdl2shim.h"

LOG_MODULE_REGISTER(dbx_present, CONFIG_SDL2SHIM_LOG_LEVEL);

#define FB_W 640
#define FB_H 400

static const struct device *display_dev;
static uint32_t backbuf[FB_W * FB_H];
static bool ready;

static int src_w, src_h;
static uint16_t xmap[FB_W]; /* src column for each dst column */

int s2s_present_init(int width, int height)
{
	src_w = width;
	src_h = height;

	for (int x = 0; x < FB_W; x++) {
		int sx = (int)((int64_t)x * src_w / FB_W);

		xmap[x] = (uint16_t)(sx < src_w ? sx : src_w - 1);
	}

	if (ready) {
		LOG_INF("present: mode -> %dx%d (VFB %dx%d)", src_w, src_h, FB_W, FB_H);
		return 0;
	}

	display_dev = DEVICE_DT_GET(DT_CHOSEN(zephyr_display));
	if (!device_is_ready(display_dev)) {
		LOG_ERR("present: display device not ready -- HDMI not connected?");
		return -ENODEV;
	}

	struct display_capabilities caps;

	display_get_capabilities(display_dev, &caps);
	LOG_INF("present: VFB %ux%u (HVS virt) fmt=0x%x; first src %dx%d",
		caps.x_resolution, caps.y_resolution,
		(unsigned int)caps.current_pixel_format, src_w, src_h);

	if (caps.x_resolution != FB_W || caps.y_resolution != FB_H) {
		LOG_WRN("present: display reports %ux%u, expected %ux%u "
			"(check render-width/render-height in overlay)",
			caps.x_resolution, caps.y_resolution, FB_W, FB_H);
	}

	ready = true;
	return 0;
}

void s2s_present_frame(const void *xrgb_pixels, int pitch)
{
	if (!ready || src_w <= 0 || src_h <= 0) {
		return;
	}

	const uint8_t *src_base = xrgb_pixels;
	uint32_t *dst = backbuf;

	for (int y = 0; y < FB_H; y++) {
		int sy = (int)((int64_t)y * src_h / FB_H);

		if (sy >= src_h) {
			sy = src_h - 1;
		}
		const uint32_t *srow = (const uint32_t *)(src_base + (size_t)sy * pitch);

		if (src_w == FB_W) {
			/* DOOM fast path: 1:1 columns, just force alpha */
			for (int x = 0; x < FB_W; x++) {
				dst[x] = 0xFF000000u | (srow[x] & 0x00FFFFFFu);
			}
		} else {
			for (int x = 0; x < FB_W; x++) {
				dst[x] = 0xFF000000u | (srow[xmap[x]] & 0x00FFFFFFu);
			}
		}
		dst += FB_W;
	}

	struct display_buffer_descriptor desc = {
		.buf_size = sizeof(backbuf),
		.width = FB_W,
		.height = FB_H,
		.pitch = FB_W,
		.frame_incomplete = false,
	};

	int rc = display_write(display_dev, 0, 0, &desc, backbuf);

	if (rc != 0) {
		LOG_ERR("present: display_write rc=%d", rc);
	}
}
```

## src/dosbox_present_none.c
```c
/*
 * SPDX-License-Identifier: Apache-2.0
 *
 * PiZZa DOSBox-X -- discard present backend (CONFIG_DOSBOX_PRESENT_NONE).
 */

#include <zephyr/kernel.h>

#include "sdl2shim.h"

int s2s_present_init(int width, int height)
{
	ARG_UNUSED(width);
	ARG_UNUSED(height);
	return 0;
}

void s2s_present_frame(const void *pixels, int pitch)
{
	ARG_UNUSED(pixels);
	ARG_UNUSED(pitch);
}
```

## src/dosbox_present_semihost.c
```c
/*
 * SPDX-License-Identifier: Apache-2.0
 *
 * PiZZa DOSBox-X -- semihosting capture present backend
 * (CONFIG_DOSBOX_PRESENT_SEMIHOST, qemu sim gates). Doom-port pattern:
 * frames land on the host as binary PPM (P6); pixels are 32bpp XRGB.
 *
 * Frame 1 is always written; every CONFIG_DOSBOX_CAPTURE_EVERY'th
 * frame after that. Mode changes reset the counter so the first frame
 * of each new mode is captured too.
 */

#include <zephyr/kernel.h>
#include <zephyr/arch/common/semihost.h>
#include <zephyr/logging/log.h>
#include <stdio.h>

#include "sdl2shim.h"

LOG_MODULE_REGISTER(dbx_present, CONFIG_SDL2SHIM_LOG_LEVEL);

#define MAX_W 1280

static int fb_w;
static int fb_h;
static uint32_t frames;
static uint32_t captures;

int s2s_present_init(int width, int height)
{
	if (width > MAX_W) {
		return -1;
	}
	fb_w = width;
	fb_h = height;
	frames = 0;
	LOG_INF("present: semihost capture backend (%dx%d)", width, height);
	return 0;
}

void s2s_present_frame(const void *xrgb_pixels, int pitch)
{
	frames++;

	bool capture = (frames == 1);

	if (CONFIG_DOSBOX_CAPTURE_EVERY > 0 &&
	    (frames % CONFIG_DOSBOX_CAPTURE_EVERY) == 0) {
		capture = true;
	}
	if (!capture) {
		return;
	}

	char name[48];
	char header[32];

	snprintf(name, sizeof(name), "dosbox_frame_%06u.ppm", ++captures);

	long fd = semihost_open(name, SEMIHOST_OPEN_WB);

	if (fd < 0) {
		LOG_ERR("present: semihost_open(%s) = %ld", name, fd);
		return;
	}

	int hlen = snprintf(header, sizeof(header), "P6\n%d %d\n255\n", fb_w, fb_h);

	semihost_write(fd, header, hlen);

	static uint8_t rowbuf[MAX_W * 3];
	const uint8_t *row = xrgb_pixels;

	for (int y = 0; y < fb_h; y++) {
		const uint32_t *px = (const uint32_t *)row;
		uint8_t *o = rowbuf;

		for (int x = 0; x < fb_w; x++) {
			uint32_t p = px[x];

			*o++ = (uint8_t)(p >> 16);
			*o++ = (uint8_t)(p >> 8);
			*o++ = (uint8_t)(p);
		}
		semihost_write(fd, rowbuf, (long)fb_w * 3);
		row += pitch;
	}
	semihost_close(fd);
	LOG_INF("present: wrote %s (frame %u, %dx%d)", name, frames, fb_w, fb_h);
}
```

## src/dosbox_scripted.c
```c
/*
 * SPDX-License-Identifier: Apache-2.0
 *
 * PiZZa DOSBox-X -- scripted keyboard input for sim verification
 * (CONFIG_DOSBOX_SCRIPTED_INPUT). Armed at the AT_PROMPT VM event;
 * dbx_scripted_pump() (called from GFX_Events) then drips one
 * keystroke every SCRIPT_KEY_MS through the real event path:
 * SDL_PushEvent -> MAPPER_CheckEvent -> KEYBOARD_AddKey -> INT9/INT16
 * -> COMMAND.COM. Pacing keeps the 16-slot BIOS keyboard buffer happy
 * while commands execute.
 */

#include <zephyr/kernel.h>
#include <zephyr/sys/printk.h>
#include <string.h>

#include "SDL.h"

#define SCRIPT_KEY_MS   100
#define SCRIPT_CMD_MS   4000 /* settle time after Enter (command runs) */
#define SCRIPT_START_MS 1500

/* P2d go/no-go: mount the baked DOOM HDD, launch DOOM.EXE (DOS/4GW,
 * protected mode -> exercises the dynrec) as a timedemo. -timedemo
 * replays demo1 as fast as possible then prints the timing to the DOS
 * console and exits -- a strong dynrec correctness check (any codegen
 * bug desyncs the demo).
 *
 * With BT input in the image (CONFIG_BTINPUT) the build exists to be
 * PLAYED: launch DOOM interactive instead. The pad's remapped keys
 * cannot type at the DOS prompt, so the script still does the mount +
 * launch; the human takes over at the title screen.
 */
static const char script[] =
	"imgmount c /doom.img -t hdd -fs fat\n"
	"c:\n"
	"dir\n"
#ifdef CONFIG_BTINPUT
	"doom\n";
#else
	"doom -timedemo demo1\n";
#endif

static bool armed;
static Uint32 t_armed;
static Uint32 t_last;
static size_t s_pos;

static SDL_Scancode char_scancode(char c)
{
	if (c >= 'a' && c <= 'z') {
		return (SDL_Scancode)(SDL_SCANCODE_A + (c - 'a'));
	}
	if (c >= '1' && c <= '9') {
		return (SDL_Scancode)(SDL_SCANCODE_1 + (c - '1'));
	}
	switch (c) {
	case '0': return SDL_SCANCODE_0;
	case ' ': return SDL_SCANCODE_SPACE;
	case '\n': return SDL_SCANCODE_RETURN;
	case '.': return SDL_SCANCODE_PERIOD;
	case '/': return SDL_SCANCODE_SLASH;
	case '-': return SDL_SCANCODE_MINUS;
	case ':': return SDL_SCANCODE_SEMICOLON; /* shifted below */
	default: return SDL_SCANCODE_UNKNOWN;
	}
}

static void push_key(SDL_Scancode sc, bool down)
{
	SDL_Event ev;

	memset(&ev, 0, sizeof(ev));
	ev.type = down ? SDL_KEYDOWN : SDL_KEYUP;
	ev.key.state = down ? SDL_PRESSED : SDL_RELEASED;
	ev.key.keysym.scancode = sc;
	ev.key.keysym.sym = SDL_GetKeyFromScancode(sc);
	SDL_PushEvent(&ev);
}

/* ':' needs shift+; -- wrap the pair in LSHIFT make/break */
static void type_char(char c)
{
	SDL_Scancode sc = char_scancode(c);

	if (sc == SDL_SCANCODE_UNKNOWN) {
		return;
	}
	if (c == ':') {
		push_key(SDL_SCANCODE_LSHIFT, true);
	}
	push_key(sc, true);
	push_key(sc, false);
	if (c == ':') {
		push_key(SDL_SCANCODE_LSHIFT, false);
	}
}

/* called from VM_Boot_DOSBox_Kernel at the AT_PROMPT VM event */
void dbx_scripted_at_prompt(void)
{
	if (armed) {
		return;
	}
	armed = true;
	t_armed = SDL_GetTicks();
	t_last = 0;
	printk("[dbx] scripted input armed\n");
}

/* called from GFX_Events on every pump */
void dbx_scripted_pump(void)
{
	if (!armed || script[s_pos] == '\0') {
		return;
	}

	Uint32 now = SDL_GetTicks();

	if (now - t_armed < SCRIPT_START_MS) {
		return;
	}

	Uint32 gap = (s_pos > 0 && script[s_pos - 1] == '\n') ? SCRIPT_CMD_MS
							       : SCRIPT_KEY_MS;

	if (t_last != 0 && now - t_last < gap) {
		return;
	}
	t_last = now;
	type_char(script[s_pos]);
	s_pos++;
	if (script[s_pos] == '\0') {
		printk("[dbx] scripted input complete\n");
	}
}
```

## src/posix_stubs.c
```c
/* POSIX stubs for calls that stay unimplemented on the shim. The real
 * file API (open/read/write/lseek/close/fstat/stat/access) lives in
 * dosbox_assets.c, backed by baked assets.
 */
#include <stdio.h>
#include <sys/types.h>
#include <sys/stat.h>
#include <errno.h>

int chmod(const char *path, mode_t mode)
{
	(void)path; (void)mode;
	errno = ENOENT;
	return -1;
}

int rmdir(const char *path)
{
	(void)path;
	errno = ENOENT;
	return -1;
}

int ftruncate(int fd, off_t length)
{
	(void)fd; (void)length;
	errno = EBADF;
	return -1;
}

int futimens(int fd, const void *times)
{
	(void)fd; (void)times;
	errno = EBADF;
	return -1;
}

int fcntl(int fd, int cmd, ...)
{
	(void)fd; (void)cmd;
	errno = EBADF;
	return -1;
}

int flock(int fd, int operation)
{
	(void)fd; (void)operation;
	return 0;
}

char *realpath(const char *path, char *resolved)
{
	(void)path; (void)resolved;
	errno = ENOENT;
	return NULL;
}

int isatty(int fd)
{
	(void)fd;
	return 0;
}

FILE *popen(const char *command, const char *type)
{
	(void)command; (void)type;
	errno = ENOSYS;
	return NULL;
}

int pclose(FILE *stream)
{
	(void)stream;
	return -1;
}

char *getcwd(char *buf, size_t size)
{
	if (buf == NULL || size < 2) {
		errno = ERANGE;
		return NULL;
	}
	buf[0] = '/';
	buf[1] = '\0';
	return buf;
}

int gethostname(char *name, size_t len)
{
	(void)name; (void)len;
	errno = ENOSYS;
	return -1;
}

#include <zephyr/kernel.h>
#include <time.h>

int clock_gettime(clockid_t clock_id, struct timespec *tp)
{
	(void)clock_id;
	if (tp == NULL) {
		errno = EINVAL;
		return -1;
	}

	int64_t ms = k_uptime_get();

	tp->tv_sec = ms / 1000;
	tp->tv_nsec = (ms % 1000) * 1000000L;
	return 0;
}
```
